# platform_designer_hps_system_hps_0_hps register map
Vendor: default_vendor.com; File version: 0.0
Registers are 32-bit, read-write, reset 0x0 unless marked. A register's access mark holds for its fields unless they carry their own. Offsets are from the block's base; [hi:lo] are bit positions; {n}, {i} and the like mark numbered series; 'fields as' and 'values as' point back to an identical list.

## nandregs — Registers in the NAND Flash Controller module accessible via its register AXI slave
Base 0xFFB80000
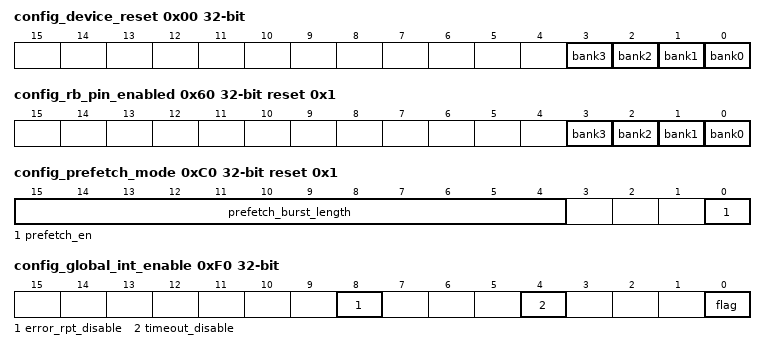
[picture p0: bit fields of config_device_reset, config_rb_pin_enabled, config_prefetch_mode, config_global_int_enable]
0x00 config_device_reset — Device reset. Controller sends a RESET command to device. Controller resets bit after sending command to device
  [n] bank{n} (n=0..3) — Issues reset to bank {n}. Controller resets the bit after reset command is issued to device.
0x10 config_transfer_spare_reg — Default data transfer mode. (Ignored during Spare only mode)
  [0] flag — On all read or write commands through Map 01, if this bit is set, data in spare area of memory will be transfered to host along with main area of data. The main area will be transfered followed by spare area.[list][*]1 - MAIN+SPARE [*]0 - MAIN[/list]
0x20 config_load_wait_cnt reset 0x1F4 — Wait count value for Load operation
  [15:0] value — Number of clock cycles after issue of load operation before NAND Flash Controller polls for status. This values is of relevance for status polling mode of operation and has been provided to minimize redundant polling after issuing a command. After a load command, the first polling will happen after this many number of cycles have elapsed and then on polling will happen every int_mon_cyccnt cycles. The default values is equal to the default value of int_mon_cyccnt
0x30 config_program_wait_cnt reset 0x1F4 — Wait count value for Program operation
  [15:0] value — Number of clock cycles after issue of program operation before NAND Flash Controller polls for status. This values is of relevance for status polling mode of operation and has been provided to minimize redundant polling after issuing a command. After a program command, the first polling will happen after this many number of cycles have elapsed and then on polling will happen every int_mon_cyccnt cycles. The default values is equal to the default value of int_mon_cyccnt. The controller internally multiplies the value programmed into this register by 16 to provide a wider range for polling.
0x40 config_erase_wait_cnt reset 0x1F4 — Wait count value for Erase operation
  [15:0] value — Number of clock cycles after issue of erase operation before NAND Flash Controller polls for status. This values is of relevance for status polling mode of operation and has been provided to minimize redundant polling after issuing a command. After a erase command, the first polling will happen after this many number of cycles have elapsed and then on polling will happen every int_mon_cyccnt cycles. The default values is equal to the default value of int_mon_cyccnt. The controller internally multiplies the value programmed into this register by 16 to provide a wider range for polling.
0x50 config_int_mon_cyccnt reset 0x1F4 — Interrupt monitor cycle count value
  [15:0] value — In polling mode, sets the number of cycles Denali Flash Controller must wait before checking the status register. This register is only used when R/B pins are not available to NAND Flash Controller.
0x60 config_rb_pin_enabled reset 0x1 — Interrupt or polling mode. Ready/Busy pin is enabled from device.
  [n] bank{n} (n=0..3) — Sets Denali Flash Controller in interrupt pin or polling mode [list][*]1 - R/B pin enabled for bank {n}. Interrupt pin mode. [*]0 - R/B pin disabled for bank {n}. Polling mode.[/list]
0x70 config_multiplane_operation — Multiplane transfer mode. Pipelined read, copyback, erase and program commands are transfered in multiplane mode
  [0] flag — [list][*]1 - Multiplane operation enabled [*]0 - Multiplane operation disabled[/list]
0x80 config_multiplane_read_enable — Device supports multiplane read command sequence
  [0] flag — Certain devices support dedicated multiplane read command sequences to read data in the same fashion as is written with multiplane program commands. This bit set should be set for the above devices. When not set, pipeline reads in multiplane mode will still happen in the order of multiplane writes, though normal read command sequences will be issued to the device. [list][*]1 - Device supports multiplane read sequence [*]0 - Device does not support multiplane read sequence[/list]
0x90 config_copyback_disable — Device does not support copyback command sequence
  [0] flag — [list][*]1 - Copyback disabled [*]0 - Copyback enabled[/list]
0xA0 config_cache_write_enable — Device supports cache write command sequence
  [0] flag — [list][*]1 - Cache write supported [*]0 - Cache write not supported[/list]
0xB0 config_cache_read_enable — Device supports cache read command sequence
  [0] flag — [list][*]1 - Cache read supported [*]0 - Cache read not supported[/list]
0xC0 config_prefetch_mode reset 0x1 — Enables read data prefetching to faster performance
  [15:4] prefetch_burst_length — If prefetch_en is set and prefetch_burst_length is set to ZERO, the controller will start prefetching data only after the receiving the first Map01 read command for the page. If prefetch_en is set and prefetch_burst_length is set to a non-ZERO, valid value, the controller will start prefetching data corresponding to this value even before the first Map01 for the current page has been received. The value written here should be in bytes.
  [0] prefetch_en — Enable prefetch of Data
0xD0 config_chip_enable_dont_care — Device can work in the chip enable dont care mode
  [0] flag — Controller can interleave commands between banks when this feature is enabled. [list][*]1 - Device in dont care mode [*]0 - Device cares for chip enable[/list]
0xE0 config_ecc_enable reset 0x1 — Enable controller ECC check bit generation and correction
  [0] flag — Enables or disables controller ECC capabilities. When enabled, controller calculates ECC check-bits and writes them onto device on program operation. On page reads, check-bits are recomputed and errors reported, if any, after comparing with stored check-bits. When disabled, controller does not compute check-bits. [list][*]1 - ECC Enabled [*]0 - ECC disabled[/list]
0xF0 config_global_int_enable — Global Interrupt enable and Error/Timeout disable.
  [8] error_rpt_disable — Command and ECC uncorrectable failures will not be reported when this bit is set
  [4] timeout_disable — Watchdog timer logic will be de-activated when this bit is set.
  [0] flag — Host will receive an interrupt only when this bit is set.
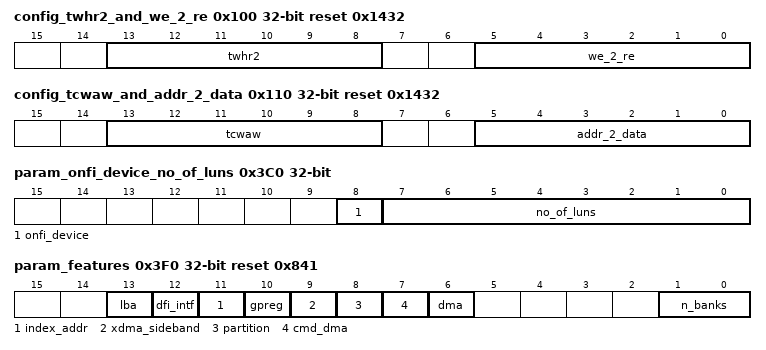
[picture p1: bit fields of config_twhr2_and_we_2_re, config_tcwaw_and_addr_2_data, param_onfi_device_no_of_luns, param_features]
0x100 config_twhr2_and_we_2_re reset 0x1432
  [13:8] twhr2 — Signifies the number of controller clocks that should be introduced between the last command of a random data output command to the start of the data transfer.
  [5:0] we_2_re — Signifies the number of bus interface nand_mp_clk clocks that should be introduced between write enable going high to read enable going low. The number of clocks is the function of device parameter Twhr and controller clock frequency.
0x110 config_tcwaw_and_addr_2_data reset 0x1432
  [13:8] tcwaw — Signifies the number of controller clocks that should be introduced between the command cycle of a random data input command to the address cycle of the random data input command.
  [5:0] addr_2_data — Signifies the number of bus interface nand_mp_clk clocks that should be introduced between address latch enable going low to write enable going low. The number of clocks is the function of device parameter Tadl and controller clock frequency.
0x120 config_re_2_we reset 0x32 — Timing parameter between re high to we low (Trhw)
  [5:0] value — Signifies the number of bus interface nand_mp_clk clocks that should be introduced between read enable going high to write enable going low. The number of clocks is the function of device parameter Trhw and controller clock frequency.
0x130 config_acc_clks — Timing parameter from read enable going low to capture read data
  [3:0] value — Signifies the number of bus interface nand_mp_clk clock cycles, controller should wait from read enable going low to sending out a strobe of nand_mp_clk for capturing of incoming data.
0x140 config_number_of_planes — Number of planes in the device
  [2:0] value — Controller will read Electronic Signature of devices and populate this field as the number of planes information is present in the signature. For 512B device, this information needs to be programmed by software. Software could also choose to override the populated value. The values in the fields should be as follows[list] [*]3'h0 - Monoplane device [*]3'h1 - Two plane device [*]3'h3 - 4 plane device [*]3'h7 - 8 plane device [*]All other values - Reserved[/list]
0x150 config_pages_per_block — Number of pages in a block
  [15:0] value — Controller will read Electronic Signature of devices and populate this field. The PAGE512 field of the System Manager NANDGRP_BOOTSTRAP register will determine the value of this field to be of 32. Software could also choose to override the populated value.
0x160 config_device_width reset 0x3 — I/O width of attached devices
  [1:0] value — Controller will read Electronic Signature of devices and populate this field. Software could also choose to override the populated value although only one value is supported. The values in this field should be as follows[list][*]2'h00 - 8bit device[*]All other values - Reserved[/list]
0x170 config_device_main_area_size — Page main area size of device in bytes
  [15:0] value — Controller will read Electronic Signature of devices and populate this field. The PAGE512 field of the System Manager NANDGRP_BOOTSTRAP register will determine the value of this field to be 512. Software could also choose to override the populated value.
0x180 config_device_spare_area_size — Page spare area size of device in bytes
  [15:0] value — Controller will read Electronic Signature of devices and populate this field. The PAGE512 field of the System Manager NANDGRP_BOOTSTRAP register will determine the value of this field to be 16. Software could also choose to override the populated value.
0x190 config_two_row_addr_cycles — Attached device has only 2 ROW address cycles
  [0] flag — This flag must be set for devices which allow for 2 ROW address cycles instead of the usual 3. Alternatively, the TWOROWADDR field of the System Manager NANDGRP_BOOTSTRAP register when asserted will set this flag.
0x1A0 config_multiplane_addr_restrict — Address restriction for multiplane commands
  [0] flag — This flag must be set for devices which require that during multiplane operations all but the address for the last plane should have their address cycles tied low. The last plane address cycles has proper values. This ensures multiplane address restrictions in the device.
0x1B0 config_ecc_correction reset 0x8 — Correction capability required
  [7:0] value — The required correction capability can be a number less than the configured error correction capability. A smaller correction capability will lead to lesser number of ECC check-bits being written per ECC sector.
0x1C0 config_read_mode — The type of read sequence that the controller will follow for pipe read commands.
  [3:0] value — The values in the field should be as follows[list] [*]4'h0 - This value informs the controller that the pipe read sequence to follow is of a normal read. For 512 byte page devices, Normal read sequence is, C00, Address, Data, ..... For devices with page size greater that 512 bytes, the sequence is, C00, Address, C30, Data..... [*]4'h1 - This value informs the controller that the pipe read sequence to follow is of a Cache Read with the following sequence, C00, Address, C30, C31, Data, C31, Data, ....., C3F, Data. [*]4'h2 - This value informs the controller that the pipe read sequence to follow is of a Cache Read with the following sequence, C00, Address, C31, Data, Data, ....., C34. [*]4'h3 - This value informs the controller that the pipe read sequence to follow is of a 'N' Plane Read with the following sequence, C00, Address, C00, Address, C30, Data, C06, Address, CE0, Data..... [*]4'h4 - This value informs the controller that the pipe read sequence to follow is of a 'N' Plane Read with the following sequence, C60, Address, C60, Address, C30, C00, Address, C05, Address, CE0, Data, C00, Address, C05, Address, CE0, Data..... [*]4'h5 - This value informs the controller that the pipe read sequence to follow is of a 'N' Plane Cache Read with the following sequence, C60, Address, C60, Address, C30, C31, C00, Address, C05, Address, CE0, Data, C00, Address, C05, Address, CE0, Data, ....., C3F, C00, Address, C05, Address, CE0, Data, C00, Address, C05, Address, CE0, Data [*]4'h6 - This value informs the controller that the pipe read sequence to follow is of a 'N' Plane Read with the following sequence, C00, Address, C32, .., C00, Address, C30, C06, Address, CE0, Data, C06, Address, CE0, Data,.... [*]4'h7 - This value informs the controller that the pipe read sequence to follow is of a 'N' Plane Cache Read with the following sequence, C00, Address, C32,..., C00, Address, C30, C31,C06, Address, CE0, Data, C31, C06, Address, CE0, Data, C3F, C06, Address, CE0, Data.... [*]4'h8 - This value informs the controller that the pipe read sequence to follow is of a 'N' Plane Cache Read with the following sequence, C60, Address, C60, Address, C33, C31, C00, Address, C05, Address, CE0, Data, C00, Address, C05, Address, CE0, Data, ....., C3F, C00, Address, C05, Address, CE0, Data, C00, Address, C05, Address, CE0, Data [*]4'h9 - 4'h15 - Reserved. [/list] ..... indicates that the previous sequence is repeated till the last page.
0x1D0 config_write_mode — The type of write sequence that the controller will follow for pipe write commands.
  [3:0] value — The values in the field should be as follows[list] [*]4'h0 - This value informs the controller that the pipe write sequence to follow is of a normal write with the following sequence, C80, Address, Data, C10..... [*]4'h1 - This value informs the controller that the pipe write sequence to follow is of a Cache Program with the following sequence, C80, Address, Data, C15, ....., C80, Address, Data, C10. [*]4'h2 - This value informs the controller that the pipe write sequence to follow is of a Two/Four Plane Program with the following sequence, C80, Address, Data, C11, C81, Address, Data, C10..... [*]4'h3 - This value informs the controller that the pipe write sequence to follow is of a 'N' Plane Program with the following sequence, C80, Address, Data, C11, C80, Address, Data, C10..... [*]4'h4 - This value informs the controller that the pipe write sequence to follow is of a 'N' Plane Cache Program with the following sequence, C80, Address, Data, C11, C80, Address, Data, C15.....C80, Address, Data, C11, C80, Address, Data, C10. [*]4'h5 - This value informs the controller that the pipe write sequence to follow is of a 'N' Plane Cache Program with the following sequence, C80, Address, Data, C11, C81, Address, Data, C15.....C80, Address, Data, C11, C81, Address, Data, C10. [*]4'h6 - 4'h15 - Reserved. [/list] ..... indicates that the previous sequence is repeated till the last page.
0x1E0 config_copyback_mode — The type of copyback sequence that the controller will follow.
  [3:0] value — The values in the field should be as follows[list] [*]4'h0 - This value informs the controller that the copyback sequence to follow is, C00, Address, C35, C85, Address, C10 [*]4'h1 - This value informs the controller that the copyback sequence to follow is, C00, Address, C30, C8C, Address, C10 [*]4'h2 - This value informs the controller that the copyback sequence to follow is, C00, Address, C8A, Address, C10 [*]4'h3 - This value informs the controller that the copyback sequence to follow is of a four plane copyback sequence, C00, Address, C03, Address, C03, Address, C03, Address, C8A, Address, C11, C8A, Address, C11, C8A, Address, C11, C8A, Address, C10. [*]4'h4 - This value informs the controller that the copyback sequence to follow is of a two plane copyback sequence, C00, Address, C35, C00, Address, C35, C85, Address, C11, C81, Address, C10. [*]4'h5 - This value informs the controller that the copyback sequence to follow is of a two plane copyback sequence, C60, Address, C60, Address, C35, C85, Address, C11, C81, Address, C10. [*]4'h6 - This value informs the controller that the copyback sequence to follow is of a two plane copyback sequence, C00, Address, C00, Address, C35, C85, Address, C11, C80, Address, C10. [*]4'h7 - This value informs the controller that the copyback sequence to follow is of a two plane copyback sequence, C60, Address, C60, Address, C30, C8C, Address, C11, C8C, Address, C10. [*]4'h8 - 4'h15 - Reserved.[/list]
0x1F0 config_rdwr_en_lo_cnt reset 0x12 — Read/Write Enable low pulse width
  [4:0] value — Number of nand_mp_clk cycles that read or write enable will kept low to meet the min Trp/Twp parameter of the device. The value in this register plus rdwr_en_hi_cnt register value should meet the min cycle time of the device connected. The default value is calculated assuming the max nand_mp_clk time period of 4ns to work with ONFI Mode 0 mode of 100ns device cycle time. This assumes a 1x/4x clocking scheme.
0x200 config_rdwr_en_hi_cnt reset 0xC — Read/Write Enable high pulse width
  [4:0] value — Number of nand_mp_clk cycles that read or write enable will kept high to meet the min Treh/Tweh parameter of the device. The value in this register plus rdwr_en_lo_cnt register value should meet the min cycle time of the device connected. The default value is calculated assuming the max nand_mp_clk time period of 4ns to work with ONFI Mode 0 mode of 100ns device cycle time. This assumes a 1x/4x clocking scheme.
0x210 config_max_rd_delay — Max round trip read data delay for data capture
  [3:0] value — Number of nand_mp_clk cycles after generation of feedback nand_mp_clk pulse when it is safe to synchronize received data to nand_mp_clk domain. Data should have been registered with nand_mp_clk and stable by the time max_rd_delay cycles has elapsed. A default value of zero will mean a value of nand_mp_clk multiple minus one.
0x220 config_cs_setup_cnt reset 0x3 — Chip select setup time
  [4:0] value — Number of nand_mp_clk cycles required for meeting chip select setup time. This register refers to device timing parameter Tcs. The value in this registers reflects the extra setup cycles for chip select before read/write enable signal is set low. The default value is calculated for ONFI Timing mode 0 Tcs = 70ns and maximum nand_mp_clk period of 4ns for 1x/4x clock multiple for 16ns cycle time device. Please refer to Figure 3.3 for the relationship between the cs_setup_cnt and rdwr_en_lo_cnt values.
0x230 config_spare_area_skip_bytes — Spare area skip bytes
  [5:0] value — Number of bytes to skip from start of spare area before last ECC sector data starts. The bytes will be written with the value programmed in the spare_area_marker register. This register could be potentially used to preserve the bad block marker in the spare area by marking it good. The default value is zero which means no bytes will be skipped and last ECC sector will start from the beginning of spare area.
0x240 config_spare_area_marker reset 0xFFFF — Spare area marker value
  [15:0] value — The value that will be written in the spare area skip bytes. This value will be used by controller while in the MAIN mode of data transfer. Only the least-significant 8 bits of the field value are used.
0x250 config_devices_connected — Number of Devices connected on one bank
  [2:0] value — Indicates the number of devices connected to a bank. At reset, the value loaded is the maximum possible devices that could be connected in this configuration.
0x260 config_die_mask — Indicates the die differentiator in case of NAND devices with stacked dies.
  [7:0] value — The die_mask register information will be used for devices having address restrictions. For example, in certain Samsung devices, when the first address in a two-plane command is being sent, it is expected that the address is all zeros. But if the NAND device internally has multiple dies stacked, the die information (MSB of final row address) has to be sent. The value programmed in this register will be used to mask the address while sending out the last row address.
0x270 config_first_block_of_next_plane reset 0x1 — The starting block address of the next plane in a multi plane device.
  [15:0] value — This values informs the controller of the plane structure of the device. In case the device is a multi plane device and the value here is 1, the controller understands that the next plane starts from Block number 1 and in conjunction with the number of planes parameter can decide upon the distribution of blocks in a plane in the device.
0x280 config_write_protect reset 0x1 — This register is used to control the assertion/de-assertion of the WP# pin to the device.
  [0] flag — When the controller is in reset, the WP# pin is always asserted to the device. Once the reset is removed, the WP# is de-asserted. The software will then have to come and program this bit to assert/de-assert the same. [list][*]1 - Write protect de-assert [*]0 - Write protect assert[/list]
0x290 config_re_2_re reset 0x32 — Timing parameter between re high to re low (Trhz) for the next bank
  [5:0] value — Signifies the number of bus interface nand_mp_clk clocks that should be introduced between read enable going high to a bank to the read enable going low to the next bank. The number of clocks is the function of device parameter Trhz and controller clock frequency.
0x2A0 config_por_reset_count reset 0x13B — The number of cycles the controller waits after reset to issue the first RESET command to the device.
  [15:0] value — The controller waits for this number of cycles before issuing the first RESET command to the device. The number in this register is multiplied internally by 16 in the controller to form the final reset wait count.
0x2B0 config_watchdog_reset_count reset 0x5B9A — The number of cycles the controller waits before flagging a watchdog timeout interrupt.
  [15:0] value — The controller waits for this number of cycles before issuing a watchdog timeout interrupt. The value in this register is multiplied internally by 32 in the controller to form the final watchdog counter.
0x300 param_manufacturer_id
  [7:0] value — Manufacturer ID
0x310 param_device_id ro
  [7:0] value — Device ID. This register is updated only for Legacy NAND devices.
0x320 param_device_param_0 ro
  [7:0] value — 3rd byte relating to Device Signature. This register is updated only for Legacy NAND devices.
0x330 param_device_param_1 ro
  [7:0] value — 4th byte relating to Device Signature. This register is updated only for Legacy NAND devices.
0x340 param_device_param_2 ro
  [7:0] value — Reserved.
0x350 param_logical_page_data_size ro — Logical page data area size in bytes
  [15:0] value — Logical page spare area size in bytes. If multiple devices are connected on a single chip select, physical page data size will be multiplied by the number of devices to arrive at logical page size.
0x360 param_logical_page_spare_size ro — Logical page data area size in bytes
  [15:0] value — Logical page spare area size in bytes. If multiple devices are connected on a single chip select, physical page spare size will be multiplied by the number of devices to arrive at logical page size.
0x370 param_revision ro reset 0x5 — Controller revision number
  [15:0] value
0x380 param_onfi_device_features ro — Features supported by the connected ONFI device
  [15:0] value — The values in the field should be interpreted as follows[list] [*]Bit 0 - Supports 16 bit data bus width. [*]Bit 1 - Supports multiple LUN operations. [*]Bit 2 - Supports non-sequential page programming. [*]Bit 3 - Supports interleaved program and erase operations. [*]Bit 4 - Supports odd to even page copyback. [*]Bit 5 - Supports source synchronous. [*]Bit 6 - Supports interleaved read operations. [*]Bit 7 - Supports extended parameter page. [*]Bit 8 - Supports program page register clear enhancement. [*]Bit 9-15 - Reserved.[/list]
0x390 param_onfi_optional_commands ro — Optional commands supported by the connected ONFI device
  [15:0] value — The values in the field should be interpreted as follows[list] [*]Bit 0 - Supports page cache program command. [*]Bit 1 - Supports read cache commands. [*]Bit 2 - Supports get and set features. [*]Bit 3 - Supports read status enhanced commands. [*]Bit 4 - Supports copyback. [*]Bit 5 - Supports Read Unique Id. [*]Bit 6 - Supports Change Read Column Enhanced. [*]Bit 7 - Supports change row address. [*]Bit 8 - Supports Change small data move. [*]Bit 9 - Supports RESET Lun. [*]Bit 10-15 - Reserved.[/list]
0x3A0 param_onfi_timing_mode ro — Asynchronous Timing modes supported by the connected ONFI device
  [5:0] value — The values in the field should be interpreted as follows[list] [*]Bit 0 - Supports Timing mode 0. [*]Bit 1 - Supports Timing mode 1. [*]Bit 2 - Supports Timing mode 2. [*]Bit 3 - Supports Timing mode 3. [*]Bit 4 - Supports Timing mode 4. [*]Bit 5 - Supports Timing mode 5.[/list]
0x3B0 param_onfi_pgm_cache_timing_mode ro — Asynchronous Program Cache Timing modes supported by the connected ONFI device
  fields as param_onfi_timing_mode
0x3C0 param_onfi_device_no_of_luns — Indicates if the device is an ONFI compliant device and the number of LUNS present in the device
  [8] onfi_device — Indicates if the device is an ONFI compliant device.[list] [*]0 - Non-ONFI compliant device [*]1 - ONFI compliant device[/list]
  [7:0] no_of_luns ro — Indicates the number of LUNS present in the device
0x3D0 param_onfi_device_no_of_blocks_per_lun_l ro — Lower bits of number of blocks per LUN present in the ONFI complaint device.
  [15:0] value — Indicates the lower bits of number of blocks per LUN present in the ONFI complaint device.
0x3E0 param_onfi_device_no_of_blocks_per_lun_u ro — Upper bits of number of blocks per LUN present in the ONFI complaint device.
  [15:0] value — Indicates the upper bits of number of blocks per LUN present in the ONFI complaint device.
0x3F0 param_features ro reset 0x841 — Shows Available hardware features or attributes
  [13] lba — if set, hardware supports Toshiba LBA devices.
  [12] dfi_intf — if set, hardware supports ONFI2.x synchronous interface.
  [11] index_addr — if set, hardware support only Indexed addressing.
  [10] gpreg — if set, General purpose registers are is present in hardware.
  [9] xdma_sideband — if set, Side band DMA signals are present in hardware.
  [8] partition — if set, Partition logic is present in hardware.
  [7] cmd_dma — Not implemented.
  [6] dma — if set, DATA-DMA is present in hardware.
  [1:0] n_banks — Maximum number of banks supported by hardware. This is an encoded value. [list][*]0 - Two banks [*]1 - Four banks [*]2 - Eight banks [*]3 - Sixteen banks[/list]
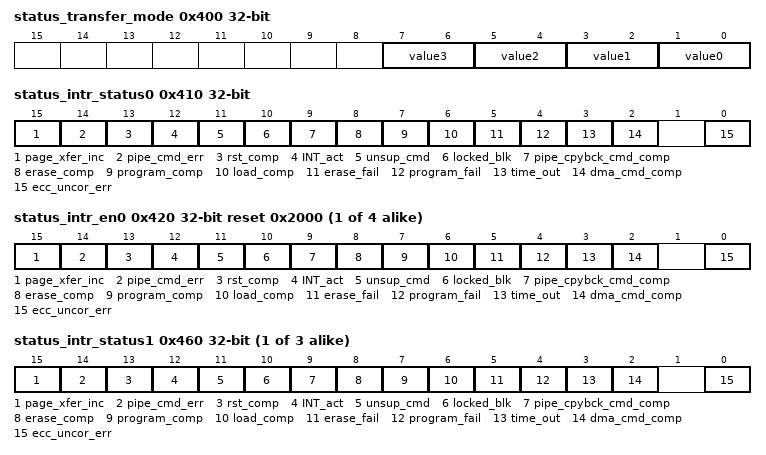
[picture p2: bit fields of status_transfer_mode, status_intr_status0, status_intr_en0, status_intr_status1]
0x400 status_transfer_mode ro — Current data transfer mode is Main only, Spare only or Main+Spare. This information is per bank.
  [2n+1:2n] value{n} (n=0..3) — [list][*]00 - Bank {n} is in Main mode [*]01 - Bank {n} is in Spare mode [*]10 - Bank {n} is in Main+Spare mode[/list]
0x410 status_intr_status0 — Interrupt status register for bank 0
  [15] page_xfer_inc write-1-clears — For every page of data transfer to or from the device, this bit will be set.
  [14] pipe_cmd_err write-1-clears — A pipeline command sequence has been violated. This occurs when Map 01 page read/write address does not match the corresponding expected address from the pipeline commands issued earlier.
  [13] rst_comp write-1-clears — Controller has finished reset and initialization process
  [12] INT_act write-1-clears — R/B pin of device transitioned from low to high
  [11] unsup_cmd write-1-clears — An unsupported command was received. This interrupt is set when an invalid command is received, or when a command sequence is broken.
  [10] locked_blk write-1-clears — The address to program or erase operation is to a locked block and the operation failed due to this reason
  [9] pipe_cpybck_cmd_comp write-1-clears — A pipeline command or a copyback bank command has completed on this particular bank
  [8] erase_comp write-1-clears — Device erase operation complete
  [7] program_comp write-1-clears — Device finished the last issued program command.
  [6] load_comp write-1-clears — Device finished the last issued load command.
  [5] erase_fail write-1-clears — Erase failure occurred in the device on issuance of a erase command. err_block_addr and err_page_addr contain the block address and page address that failed erase operation.
  [4] program_fail write-1-clears — Program failure occurred in the device on issuance of a program command. err_block_addr and err_page_addr contain the block address and page address that failed program operation.
  [3] time_out write-1-clears — Watchdog timer has triggered in the controller due to one of the reasons like device not responding or controller state machine did not get back to idle
  [2] dma_cmd_comp write-1-clears — Not implemented.
  [0] ecc_uncor_err write-1-clears — Ecc logic detected uncorrectable error while reading data from flash device.
{0x420+0x50*i} status_intr_en{i} reset 0x2000 (i=0..3) — Enables corresponding interrupt bit in interrupt register for bank {i}
  [15] page_xfer_inc — For every page of data transfer to or from the device, this bit will be set.
  [14] pipe_cmd_err — A pipeline command sequence has been violated. This occurs when Map 01 page read/write address does not match the corresponding expected address from the pipeline commands issued earlier.
  [13] rst_comp — A reset command has completed on this bank
  [12] INT_act — R/B pin of device transitioned from low to high
  [11] unsup_cmd — An unsupported command was received. This interrupt is set when an invalid command is received, or when a command sequence is broken.
  [10] locked_blk — The address to program or erase operation is to a locked block and the operation failed due to this reason
  [9] pipe_cpybck_cmd_comp — A pipeline command or a copyback bank command has completed on this particular bank
  [8] erase_comp — Device erase operation complete
  [7] program_comp — Device finished the last issued program command.
  [6] load_comp — Device finished the last issued load command.
  [5] erase_fail — Erase failure occurred in the device on issuance of a erase command. err_block_addr and err_page_addr contain the block address and page address that failed erase operation.
  [4] program_fail — Program failure occurred in the device on issuance of a program command. err_block_addr and err_page_addr contain the block address and page address that failed program operation.
  [3] time_out — Watchdog timer has triggered in the controller due to one of the reasons like device not responding or controller state machine did not get back to idle
  [2] dma_cmd_comp — Not implemented.
  [0] ecc_uncor_err — If set, Controller will interrupt processor when Ecc logic detects uncorrectable error.
{0x430+0x50*i} status_page_cnt{i} ro (i=0..3) — Decrementing page count bank {i}
  [7:0] value — Maintains a decrementing count of the number of pages in the multi-page (pipeline and copyback) command being executed.
{0x440+0x50*i} status_err_page_addr{i} ro (i=0..3) — Erred page address bank {i}
  [15:0] value — Holds the page address that resulted in a failure on program or erase operation.
{0x450+0x50*i} status_err_block_addr{i} ro (i=0..3) — Erred block address bank {i}
  [15:0] value — Holds the block address that resulted in a failure on program or erase operation.
{0x410+0x50*i} status_intr_status{i} (i=1..3) — Interrupt status register for bank {i}
  [15] page_xfer_inc write-1-clears — For every page of data transfer to or from the device, this bit will be set.
  [14] pipe_cmd_err write-1-clears — A pipeline command sequence has been violated. This occurs when Map 01 page read/write address does not match the corresponding expected address from the pipeline commands issued earlier.
  [13] rst_comp write-1-clears — The NAND Flash Memory Controller has completed its reset and initialization process
  [12] INT_act write-1-clears — R/B pin of device transitioned from low to high
  [11] unsup_cmd write-1-clears — An unsupported command was received. This interrupt is set when an invalid command is received, or when a command sequence is broken.
  [10] locked_blk write-1-clears — The address to program or erase operation is to a locked block and the operation failed due to this reason
  [9] pipe_cpybck_cmd_comp write-1-clears — A pipeline command or a copyback bank command has completed on this particular bank
  [8] erase_comp write-1-clears — Device erase operation complete
  [7] program_comp write-1-clears — Device finished the last issued program command.
  [6] load_comp write-1-clears — Device finished the last issued load command.
  [5] erase_fail write-1-clears — Erase failure occurred in the device on issuance of a erase command. err_block_addr and err_page_addr contain the block address and page address that failed erase operation.
  [4] program_fail write-1-clears — Program failure occurred in the device on issuance of a program command. err_block_addr and err_page_addr contain the block address and page address that failed program operation.
  [3] time_out write-1-clears — Watchdog timer has triggered in the controller due to one of the reasons like device not responding or controller state machine did not get back to idle
  [2] dma_cmd_comp write-1-clears — Not implemented.
  [0] ecc_uncor_err write-1-clears — Ecc logic detected uncorrectable error while reading data from flash device.
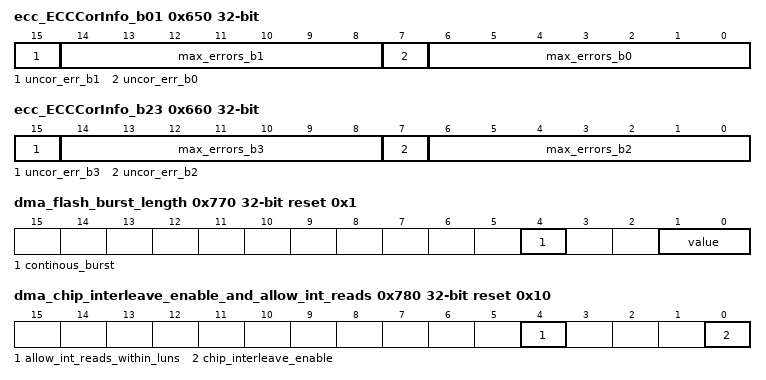
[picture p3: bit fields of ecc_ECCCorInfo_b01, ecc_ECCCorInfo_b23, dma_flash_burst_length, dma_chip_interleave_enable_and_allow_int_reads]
0x650 ecc_ECCCorInfo_b01 ro — ECC Error correction Information register. Controller updates this register when it completes a transaction. The values are held in this register till a new transaction completes.
  [15] uncor_err_b1 — Uncorrectable error occurred while reading pages for last transaction in Bank1. Uncorrectable errors also generate interrupts in intr_statusx register.
  [14:8] max_errors_b1 — Maximum of number of errors corrected per sector in Bank1. This field is not valid for uncorrectable errors. A value of zero indicates that no ECC error occurred in last completed transaction.
  [7] uncor_err_b0 — Uncorrectable error occurred while reading pages for last transaction in Bank0. Uncorrectable errors also generate interrupts in intr_statusx register.
  [6:0] max_errors_b0 — Maximum of number of errors corrected per sector in Bank0. This field is not valid for uncorrectable errors. A value of zero indicates that no ECC error occurred in last completed transaction.
0x660 ecc_ECCCorInfo_b23 ro — ECC Error correction Information register. Controller updates this register when it completes a transaction. The values are held in this register till a new transaction completes.
  [15] uncor_err_b3 — Uncorrectable error occurred while reading pages for last transaction in Bank3. Uncorrectable errors also generate interrupts in intr_statusx register.
  [14:8] max_errors_b3 — Maximum of number of errors corrected per sector in Bank3. This field is not valid for uncorrectable errors. A value of zero indicates that no ECC error occurred in last completed transaction.
  [7] uncor_err_b2 — Uncorrectable error occurred while reading pages for last transaction in Bank2. Uncorrectable errors also generate interrupts in intr_statusx register.
  [6:0] max_errors_b2 — Maximum of number of errors corrected per sector in Bank2. This field is not valid for uncorrectable errors. A value of zero indicates that no ECC error occurred in last completed transaction.
0x700 dma_dma_enable
  [0] flag — Enables data DMA operation in the controller 1 - Enable DMA 0 - Disable DMA
0x720 dma_dma_intr — DMA interrupt register
  [0] target_error write-1-clears — Controller initiator interface received an ERROR target response for a transaction.
0x730 dma_dma_intr_en — Enables corresponding interrupt bit in dma interrupt register
  [0] target_error — Controller initiator interface received an ERROR target response for a transaction.
0x740 dma_target_err_addr_lo ro — Transaction address for which controller initiator interface received an ERROR target response.
  [15:0] value — Least significant 16 bits
0x750 dma_target_err_addr_hi ro — Transaction address for which controller initiator interface received an ERROR target response.
  [15:0] value — Most significant 16 bits
0x770 dma_flash_burst_length reset 0x1
  [4] continous_burst — When this bit is set, the Data DMA will burst the entire page from/to the flash device. Please make sure that the host system can provide/sink data at a fast pace to avoid unnecessary pausing of data on the device interface.
  [1:0] value — Sets the burst used by data dma for transferring data to/from flash device. This burst length is different and is larger than the burst length on the host bus so that larger amount of data can be transferred to/from device, descreasing controller data transfer overhead in the process. 00 - 64 bytes, 01 - 128 bytes, 10 - 256 bytes, 11 - 512 bytes. The host burst size multiplied by the number of outstanding requests on the host side should be greater than equal to this value. If not, the device side burst length will be equal to host side burst length.
0x780 dma_chip_interleave_enable_and_allow_int_reads reset 0x10
  [4] allow_int_reads_within_luns — This bit informs the controller to enable or disable simultaneous read accesses to different LUNS in the same bank. This bit is of importance only if the controller supports interleaved operations among LUNs and if the device has multiple LUNS. If the bit is disabled, the controller will send read commands to different LUNS of of the same bank only sequentially and if enabled, the controller will issue simultaneous read accesses to LUNS of same bank if required. [list][*]1 - Enable [*]0 - Disable[/list]
  [0] chip_interleave_enable — This bit informs the controller to enable or disable interleaving among banks/LUNS to increase the net performance of the controller. [list][*]1 - Enable interleaving [*]0 - Disable Interleaving[/list]
0x790 dma_no_of_blocks_per_lun reset 0xF
  [3:0] value — Indicates the first block of next LUN. This information is used for extracting the target LUN during LUN interleaving. After Initialization, if the controller detects an ONFi device, this field is automatically updated by the controller. For other devices, software will need to write to this register for proper interleaving. The value in this register is interpreted as follows- [list][*]0 - Next LUN starts from 1024. [*]1 - Next LUN starts from 2048. [*]2 - Next LUN starts from 4096 and so on... [/list]
0x7A0 dma_lun_status_cmd reset 0x7878 — Indicates the command to be sent while checking status of the next LUN.
  [15:0] value — [list][*]7:0 - Indicates the command to check the status of the first LUN/Die. [*]15:8 - Indicates the command to check the status of the other LUN/Die.[/list]
